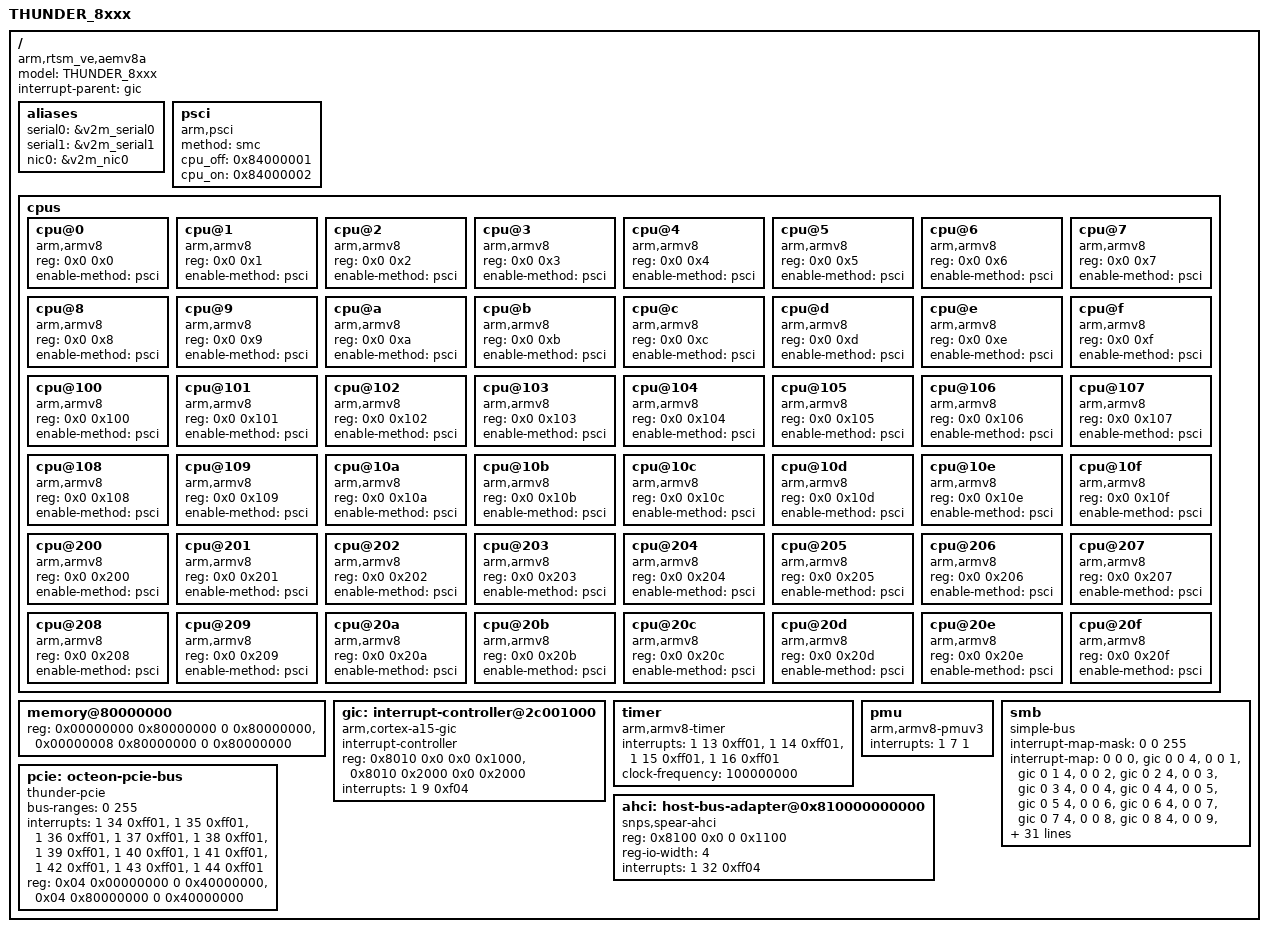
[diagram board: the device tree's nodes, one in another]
/*
 * Cavium THUNDER ARMv8 Emulation Model
 *
 * Cavium Inc.
 */

/dts-v1/;

/memreserve/ 0x80000000 0x00010000;

/ {
	model = "THUNDER_8xxx";
	compatible = "arm,rtsm_ve,aemv8a";
	interrupt-parent = <&gic>;
	#address-cells = <2>;
	#size-cells = <2>;

	aliases {
		serial0 = &v2m_serial0;
		serial1 = &v2m_serial1;
		nic0 = &v2m_nic0;
	};

	psci {
		compatible = "arm,psci";
		method = "smc";
		cpu_off = <0x84000001>;
		cpu_on = <0x84000002>;
	};

	cpus {
		#address-cells = <2>;
		#size-cells = <0>;

		cpu@0 {
			device_type = "cpu";
			compatible = "arm,armv8";
			reg = <0x0 0x0>;
			/*enable-method = "spin-table";
			cpu-release-addr = <0x0 0x8000fff8>;*/
			enable-method = "psci";
		};
		cpu@1 {
			device_type = "cpu";
			compatible = "arm,armv8";
			reg = <0x0 0x1>;
			/*enable-method = "spin-table";
			cpu-release-addr = <0x0 0x8000fff8>;*/
			enable-method = "psci";
		};
		cpu@2 {
			device_type = "cpu";
			compatible = "arm,armv8";
			reg = <0x0 0x2>;
			/*enable-method = "spin-table";
			cpu-release-addr = <0x0 0x8000fff8>;*/
			enable-method = "psci";
		};
		cpu@3 {
			device_type = "cpu";
			compatible = "arm,armv8";
			reg = <0x0 0x3>;
			/*enable-method = "spin-table";
			cpu-release-addr = <0x0 0x8000fff8>;*/
			enable-method = "psci";
		};
		cpu@4 {
			device_type = "cpu";
			compatible = "arm,armv8";
			reg = <0x0 0x4>;
			/*enable-method = "spin-table";
			cpu-release-addr= <0x0 0x8000fff8>;*/
			enable-method = "psci";
		};
		cpu@5 {
			device_type = "cpu";
			compatible = "arm,armv8";
			reg = <0x0 0x5>;
			/*enable-method = "spin-table";
			cpu-release-addr= <0x0 0x8000fff8>;*/
			enable-method = "psci";
		};
		cpu@6 {
			device_type = "cpu";
			compatible = "arm,armv8";
			reg = <0x0 0x6>;
			/*enable-method = "spin-table";
			cpu-release-addr= <0x0 0x8000fff8>;*/
			enable-method = "psci";
		};
		cpu@7 {
			device_type = "cpu";
			compatible = "arm,armv8";
			reg = <0x0 0x7>;
			/*enable-method = "spin-table";
			cpu-release-addr= <0x0 0x8000fff8>;*/
			enable-method = "psci";
		};
		cpu@8 {
			device_type = "cpu";
			compatible = "arm,armv8";
			reg = <0x0 0x8>;
			/*enable-method = "spin-table";
			cpu-release-addr = <0x0 0x8000fff8>;*/
			enable-method = "psci";
		};
		cpu@9 {
			device_type = "cpu";
			compatible = "arm,armv8";
			reg = <0x0 0x9>;
			/*enable-method = "spin-table";
			cpu-release-addr = <0x0 0x8000fff8>;*/
			enable-method = "psci";
		};
		cpu@a {
			device_type = "cpu";
			compatible = "arm,armv8";
			reg = <0x0 0xa>;
			/*enable-method = "spin-table";
			cpu-release-addr = <0x0 0x8000fff8>;*/
			enable-method = "psci";
		};
		cpu@b {
			device_type = "cpu";
			compatible = "arm,armv8";
			reg = <0x0 0xb>;
			/*enable-method = "spin-table";
			cpu-release-addr = <0x0 0x8000fff8>;*/
			enable-method = "psci";
		};
		cpu@c {
			device_type = "cpu";
			compatible = "arm,armv8";
			reg = <0x0 0xc>;
			/*enable-method = "spin-table";
			cpu-release-addr = <0x0 0x8000fff8>;*/
			enable-method = "psci";
		};
		cpu@d {
			device_type = "cpu";
			compatible = "arm,armv8";
			reg = <0x0 0xd>;
			/*enable-method = "spin-table";
			cpu-release-addr = <0x0 0x8000fff8>;*/
			enable-method = "psci";
		};
		cpu@e {
			device_type = "cpu";
			compatible = "arm,armv8";
			reg = <0x0 0xe>;
			/*enable-method = "spin-table";
			cpu-release-addr = <0x0 0x8000fff8>;*/
			enable-method = "psci";
		};
		cpu@f {
			device_type = "cpu";
			compatible = "arm,armv8";
			reg = <0x0 0xf>;
			/*enable-method = "spin-table";
			cpu-release-addr = <0x0 0x8000fff8>;*/
			enable-method = "psci";
		};
		cpu@100 {
			device_type = "cpu";
			compatible = "arm,armv8";
			reg = <0x0 0x100>;
			/*enable-method = "spin-table";
			cpu-release-addr = <0x0 0x8000fff8>;*/
			enable-method = "psci";
		};
		cpu@101 {
			device_type = "cpu";
			compatible = "arm,armv8";
			reg = <0x0 0x101>;
			/*enable-method = "spin-table";
			cpu-release-addr = <0x0 0x8000fff8>;*/
			enable-method = "psci";
		};
		cpu@102 {
			device_type = "cpu";
			compatible = "arm,armv8";
			reg = <0x0 0x102>;
			/*enable-method = "spin-table";
			cpu-release-addr = <0x0 0x8000fff8>;*/
			enable-method = "psci";
		};
		cpu@103 {
			device_type = "cpu";
			compatible = "arm,armv8";
			reg = <0x0 0x103>;
			/*enable-method = "spin-table";
			cpu-release-addr = <0x0 0x8000fff8>;*/
			enable-method = "psci";
		};
		cpu@104 {
			device_type = "cpu";
			compatible = "arm,armv8";
			reg = <0x0 0x104>;
			/*enable-method = "spin-table";
			cpu-release-addr = <0x0 0x8000fff8>;*/
			enable-method = "psci";
		};
		cpu@105 {
			device_type = "cpu";
			compatible = "arm,armv8";
			reg = <0x0 0x105>;
			/*enable-method = "spin-table";
			cpu-release-addr = <0x0 0x8000fff8>;*/
			enable-method = "psci";
		};
		cpu@106 {
			device_type = "cpu";
			compatible = "arm,armv8";
			reg = <0x0 0x106>;
			/*enable-method = "spin-table";
			cpu-release-addr = <0x0 0x8000fff8>;*/
			enable-method = "psci";
		};
		cpu@107 {
			device_type = "cpu";
			compatible = "arm,armv8";
			reg = <0x0 0x107>;
			/*enable-method = "spin-table";
			cpu-release-addr = <0x0 0x8000fff8>;*/
			enable-method = "psci";
		};
		cpu@108 {
			device_type = "cpu";
			compatible = "arm,armv8";
			reg = <0x0 0x108>;
			/*enable-method = "spin-table";
			cpu-release-addr = <0x0 0x8000fff8>;*/
			enable-method = "psci";
		};
		cpu@109 {
			device_type = "cpu";
			compatible = "arm,armv8";
			reg = <0x0 0x109>;
			/*enable-method = "spin-table";
			cpu-release-addr = <0x0 0x8000fff8>;*/
			enable-method = "psci";
		};
		cpu@10a {
			device_type = "cpu";
			compatible = "arm,armv8";
			reg = <0x0 0x10a>;
			/*enable-method = "spin-table";
			cpu-release-addr = <0x0 0x8000fff8>;*/
			enable-method = "psci";
		};
		cpu@10b {
			device_type = "cpu";
			compatible = "arm,armv8";
			reg = <0x0 0x10b>;
			/*enable-method = "spin-table";
			cpu-release-addr = <0x0 0x8000fff8>;*/
			enable-method = "psci";
		};
		cpu@10c {
			device_type = "cpu";
			compatible = "arm,armv8";
			reg = <0x0 0x10c>;
			/*enable-method = "spin-table";
			cpu-release-addr = <0x0 0x8000fff8>;*/
			enable-method = "psci";
		};
		cpu@10d {
			device_type = "cpu";
			compatible = "arm,armv8";
			reg = <0x0 0x10d>;
			/*enable-method = "spin-table";
			cpu-release-addr = <0x0 0x8000fff8>;*/
			enable-method = "psci";
		};
		cpu@10e {
			device_type = "cpu";
			compatible = "arm,armv8";
			reg = <0x0 0x10e>;
			/*enable-method = "spin-table";
			cpu-release-addr = <0x0 0x8000fff8>;*/
			enable-method = "psci";
		};
		cpu@10f {
			device_type = "cpu";
			compatible = "arm,armv8";
			reg = <0x0 0x10f>;
			/*enable-method = "spin-table";
			cpu-release-addr = <0x0 0x8000fff8>;*/
			enable-method = "psci";
		};
		cpu@200 {
			device_type = "cpu";
			compatible = "arm,armv8";
			reg = <0x0 0x200>;
			/*enable-method = "spin-table";
			cpu-release-addr = <0x0 0x8000fff8>;*/
			enable-method = "psci";
		};
		cpu@201 {
			device_type = "cpu";
			compatible = "arm,armv8";
			reg = <0x0 0x201>;
			/*enable-method = "spin-table";
			cpu-release-addr = <0x0 0x8000fff8>;*/
			enable-method = "psci";
		};
		cpu@202 {
			device_type = "cpu";
			compatible = "arm,armv8";
			reg = <0x0 0x202>;
			/*enable-method = "spin-table";
			cpu-release-addr = <0x0 0x8000fff8>;*/
			enable-method = "psci";
		};
		cpu@203 {
			device_type = "cpu";
			compatible = "arm,armv8";
			reg = <0x0 0x203>;
			/*enable-method = "spin-table";
			cpu-release-addr = <0x0 0x8000fff8>;*/
			enable-method = "psci";
		};
		cpu@204 {
			device_type = "cpu";
			compatible = "arm,armv8";
			reg = <0x0 0x204>;
			/*enable-method = "spin-table";
			cpu-release-addr = <0x0 0x8000fff8>;*/
			enable-method = "psci";
		};
		cpu@205 {
			device_type = "cpu";
			compatible = "arm,armv8";
			reg = <0x0 0x205>;
			/*enable-method = "spin-table";
			cpu-release-addr = <0x0 0x8000fff8>;*/
			enable-method = "psci";
		};
		cpu@206 {
			device_type = "cpu";
			compatible = "arm,armv8";
			reg = <0x0 0x206>;
			/*enable-method = "spin-table";
			cpu-release-addr = <0x0 0x8000fff8>;*/
			enable-method = "psci";
		};
		cpu@207 {
			device_type = "cpu";
			compatible = "arm,armv8";
			reg = <0x0 0x207>;
			/*enable-method = "spin-table";
			cpu-release-addr = <0x0 0x8000fff8>;*/
			enable-method = "psci";
		};
		cpu@208 {
			device_type = "cpu";
			compatible = "arm,armv8";
			reg = <0x0 0x208>;
			/*enable-method = "spin-table";
			cpu-release-addr = <0x0 0x8000fff8>;*/
			enable-method = "psci";
		};
		cpu@209 {
			device_type = "cpu";
			compatible = "arm,armv8";
			reg = <0x0 0x209>;
			/*enable-method = "spin-table";
			cpu-release-addr = <0x0 0x8000fff8>;*/
			enable-method = "psci";
		};
		cpu@20a {
			device_type = "cpu";
			compatible = "arm,armv8";
			reg = <0x0 0x20a>;
			/*enable-method = "spin-table";
			cpu-release-addr = <0x0 0x8000fff8>;*/
			enable-method = "psci";
		};
		cpu@20b {
			device_type = "cpu";
			compatible = "arm,armv8";
			reg = <0x0 0x20b>;
			/*enable-method = "spin-table";
			cpu-release-addr = <0x0 0x8000fff8>;*/
			enable-method = "psci";
		};
		cpu@20c {
			device_type = "cpu";
			compatible = "arm,armv8";
			reg = <0x0 0x20c>;
			/*enable-method = "spin-table";
			cpu-release-addr = <0x0 0x8000fff8>;*/
			enable-method = "psci";
		};
		cpu@20d {
			device_type = "cpu";
			compatible = "arm,armv8";
			reg = <0x0 0x20d>;
			/*enable-method = "spin-table";
			cpu-release-addr = <0x0 0x8000fff8>;*/
			enable-method = "psci";
		};
		cpu@20e {
			device_type = "cpu";
			compatible = "arm,armv8";
			reg = <0x0 0x20e>;
			/*enable-method = "spin-table";
			cpu-release-addr = <0x0 0x8000fff8>;*/
			enable-method = "psci";
		};
		cpu@20f {
			device_type = "cpu";
			compatible = "arm,armv8";
			reg = <0x0 0x20f>;
			/*enable-method = "spin-table";
			cpu-release-addr = <0x0 0x8000fff8>;*/
			enable-method = "psci";
		};
	};

	memory@80000000 {
		device_type = "memory";
		reg = <0x00000000 0x80000000 0 0x80000000>,
		      <0x00000008 0x80000000 0 0x80000000>;
	};

	gic: interrupt-controller@2c001000 {
		compatible = "arm,cortex-a15-gic", "arm,cortex-a9-gic", "cavium,thunder-gicv3";
		#interrupt-cells = <3>;
		#address-cells = <0>;
		interrupt-controller;
		reg = <0x8010 0x0 0x0 0x1000>,
		      <0x8010 0x2000 0x0 0x2000>;
		interrupts = <1 9 0xf04>;
	};

	timer {
		compatible = "arm,armv8-timer";
		interrupts = <1 13 0xff01>,
			     <1 14 0xff01>,
			     <1 15 0xff01>,
			     <1 16 0xff01>;
		clock-frequency = <100000000>;
	};

	pmu {
		compatible = "arm,armv8-pmuv3";
		interrupts = <1 7 1>;
	};

	smb {
		compatible = "simple-bus";

		#address-cells = <2>;
		#size-cells = <2>;
		ranges = <0 0 0 0x00000000 0x04000000>,
			 <1 0 0 0x14000000 0x04000000>,
			 <2 0 0 0x18000000 0x04000000>,
			 <3 0 0 0x1c000000 0x04000000>,
			 <4 0 0 0x0c000000 0x04000000>,
			 <5 0 0 0x10000000 0x04000000>;

		#interrupt-cells = <1>;
		interrupt-map-mask = <0 0 255>;
		interrupt-map = <0 0  0 &gic 0  0 4>,
				<0 0  1 &gic 0  1 4>,
				<0 0  2 &gic 0  2 4>,
				<0 0  3 &gic 0  3 4>,
				<0 0  4 &gic 0  4 4>,
				<0 0  5 &gic 0  5 4>,
				<0 0  6 &gic 0  6 4>,
				<0 0  7 &gic 0  7 4>,
				<0 0  8 &gic 0  8 4>,
				<0 0  9 &gic 0  9 4>,
				<0 0 10 &gic 0 10 4>,
				<0 0 11 &gic 0 11 4>,
				<0 0 12 &gic 0 12 4>,
				<0 0 13 &gic 0 13 4>,
				<0 0 14 &gic 0 14 4>,
				<0 0 15 &gic 0 15 4>,
				<0 0 16 &gic 0 16 4>,
				<0 0 17 &gic 0 17 4>,
				<0 0 18 &gic 0 18 4>,
				<0 0 19 &gic 0 19 4>,
				<0 0 20 &gic 0 20 4>,
				<0 0 21 &gic 0 21 4>,
				<0 0 22 &gic 0 22 4>,
				<0 0 23 &gic 0 23 4>,
				<0 0 24 &gic 0 24 4>,
				<0 0 25 &gic 0 25 4>,
				<0 0 26 &gic 0 26 4>,
				<0 0 27 &gic 0 27 4>,
				<0 0 28 &gic 0 28 4>,
				<0 0 29 &gic 0 29 4>,
				<0 0 30 &gic 0 30 4>,
				<0 0 31 &gic 0 31 4>,
				<0 0 32 &gic 0 32 4>,
				<0 0 33 &gic 0 33 4>,
				<0 0 34 &gic 0 34 4>,
				<0 0 35 &gic 0 35 4>,
				<0 0 36 &gic 0 36 4>,
				<0 0 37 &gic 0 37 4>,
				<0 0 38 &gic 0 38 4>,
				<0 0 39 &gic 0 39 4>,
				<0 0 40 &gic 0 40 4>,
				<0 0 41 &gic 0 41 4>,
				<0 0 42 &gic 0 42 4>,
				<0 0 43 &gic 0 43 4>,
				<0 0 44 &gic 0 44 4>,
				<0 0 45 &gic 0 45 4>,
				<0 0 46 &gic 0 46 4>,
				<0 0 47 &gic 0 47 4>,
				<0 0 48 &gic 0 48 4>,
				<0 0 49 &gic 0 49 4>,
				<0 0 50 &gic 0 50 4>,
				<0 0 51 &gic 0 51 4>,
				<0 0 52 &gic 0 52 4>,
				<0 0 53 &gic 0 53 4>,
				<0 0 54 &gic 0 54 4>,
				<0 0 55 &gic 0 55 4>,
				<0 0 56 &gic 0 56 4>,
				<0 0 57 &gic 0 57 4>,
				<0 0 58 &gic 0 58 4>,
				<0 0 59 &gic 0 59 4>,
				<0 0 60 &gic 0 60 4>,
				<0 0 61 &gic 0 61 4>,
				<0 0 62 &gic 0 62 4>,
				<0 0 63 &gic 0 63 4>,
				<0 0 64 &gic 0 64 4>,
				<0 0 65 &gic 0 65 4>,
				<0 0 66 &gic 0 66 4>,
				<0 0 67 &gic 0 67 4>,
				<0 0 68 &gic 0 68 4>,
				<0 0 69 &gic 0 69 4>,
				<0 0 70 &gic 0 70 4>;

		/include/ "thunder-motherboard.dtsi"
	};
	ahci: host-bus-adapter@0x810000000000 {
	      compatible = "snps,spear-ahci";
	      reg = <0x8100 0x0 0 0x1100>;
	      reg-io-width = <4>;
	      interrupts = <1 32 0xff04>;
	};

        pcie: octeon-pcie-bus {
	        compatible = "thunder-pcie", "pci";
		bus-ranges = <0 255>;
                interrupts = <1 34 0xff01>,                    /* MSI intr 50 */
			     <1 35 0xff01>,
			     <1 36 0xff01>,
			     <1 37 0xff01>,
			     <1 38 0xff01>,		      
			     <1 39 0xff01>,		     
			     <1 40 0xff01>,		    
			     <1 41 0xff01>,		     
			     <1 42 0xff01>,		    
			     <1 43 0xff01>,		   
			     <1 44 0xff01>;		       /* MSI intr 60 */
		reg =    <0x04  0x00000000 0  0x40000000>,      /* Port 0 config space */
			 <0x04  0x80000000 0  0x40000000>;      /* Port 1 config space */

	        ranges = <0x00  0x05  0x00000000 0  0x100000    /* Port 0 IO space  */
			  0x01  0x05  0xf0000000 0  0x8000000   /* Port 0 Mem space */
			  0x00  0x05  0x10000000 0  0x100000    /* Port 1 IO space  */
			  0x01  0x06  0xf0000000 0  0x8000000>; /* Port 1 Mem space */
	};
};
